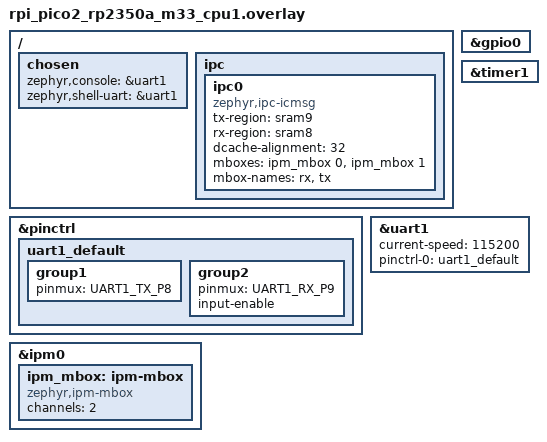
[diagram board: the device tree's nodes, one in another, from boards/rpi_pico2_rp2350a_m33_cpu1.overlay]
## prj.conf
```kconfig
CONFIG_PRINTK=y

CONFIG_IPC_SERVICE=y
CONFIG_IPC_SERVICE_BACKEND_ICMSG=y
CONFIG_MBOX=y

CONFIG_LOG=y
CONFIG_ASSERT=y

# CONFIG_ARCH_LOG_LEVEL_DBG=y
CONFIG_SOC_LOG_LEVEL_DBG=y
# CONFIG_KERNEL_LOG_LEVEL_DBG=y
CONFIG_MBOX_LOG_LEVEL_DBG=y
CONFIG_IPM_LOG_LEVEL_DBG=y
CONFIG_IPC_SERVICE_LOG_LEVEL_DBG=y
# CONFIG_LOG_DEFAULT_LEVEL=4
# CONFIG_LOG_OVERRIDE_LEVEL=4


CONFIG_LOG_MODE_DEFERRED=y
# CONFIG_LOG_MODE_MINIMAL=y
CONFIG_LOG_BUFFER_SIZE=16384
```

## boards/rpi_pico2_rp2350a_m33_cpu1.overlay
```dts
/*
 * Copyright (c) 2025 Dmitrii Sharshakov <d3dx12.xx@gmail.com>
 *
 * SPDX-License-Identifier: Apache-2.0
 */

gpio0_lo: &gpio0 {
	status = "okay";
};

&timer1 {
	status = "okay";
};

&pinctrl {
	uart1_default: uart1_default {
		group1 {
			pinmux = <UART1_TX_P8>;
		};

		group2 {
			pinmux = <UART1_RX_P9>;
			input-enable;
		};
	};
};

&uart1 {
	current-speed = <115200>;
	status = "okay";
	pinctrl-0 = <&uart1_default>;
	pinctrl-names = "default";
};

&ipm0 {
	ipm_mbox: ipm-mbox {
		compatible = "zephyr,ipm-mbox";
		#mbox-cells = <1>;
		channels = <2>;
		status = "okay";
	};
};

/ {
	chosen {
		zephyr,console = &uart1;
		zephyr,shell-uart = &uart1;
	};

	ipc {
		ipc0: ipc0 {
			compatible = "zephyr,ipc-icmsg";
			tx-region = <&sram9>;
			rx-region = <&sram8>;
			dcache-alignment = <32>;
			mboxes = <&ipm_mbox 0>, <&ipm_mbox 1>;
			mbox-names = "rx", "tx";
			status = "okay";
		};
	};
};
```

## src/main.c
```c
/*
 * Copyright (c) 2022 Nordic Semiconductor ASA
 *
 * SPDX-License-Identifier: Apache-2.0
 */

#include <zephyr/kernel.h>
#include <zephyr/device.h>

#include <zephyr/ipc/ipc_service.h>

#include "common.h"

#include <zephyr/logging/log.h>
LOG_MODULE_REGISTER(remote, LOG_LEVEL_INF);

#if defined(CONFIG_MULTITHREADING)
K_SEM_DEFINE(bound_sem, 0, 1);
#else
volatile uint32_t bound_sem = 1;
volatile uint32_t recv_sem = 1;
#endif

static unsigned char expected_message = 'a';
static size_t expected_len = PACKET_SIZE_START;
static size_t received;

static void ep_bound(void *priv)
{
	received = 0;
#if defined(CONFIG_MULTITHREADING)
	k_sem_give(&bound_sem);
#else
	bound_sem = 0;
#endif
	LOG_INF("Ep bounded");
}

static void ep_recv(const void *data, size_t len, void *priv)
{
#if defined(CONFIG_ASSERT)
	struct data_packet *packet = (struct data_packet *)data;

	__ASSERT(packet->data[0] == expected_message, "Unexpected message. Expected %c, got %c",
		expected_message, packet->data[0]);
	__ASSERT(len == expected_len, "Unexpected length. Expected %zu, got %zu",
		expected_len, len);
#endif

#ifndef CONFIG_MULTITHREADING
	recv_sem = 0;
#endif

	received += len;
	expected_message++;
	expected_len++;

	if (expected_message > 'z') {
		expected_message = 'a';
	}

	if (expected_len > sizeof(struct data_packet)) {
		expected_len = PACKET_SIZE_START;
	}
}

static int send_for_time(struct ipc_ept *ep, const int64_t sending_time_ms)
{
	struct data_packet msg = {.data[0] = 'A'};
	size_t mlen = PACKET_SIZE_START;
	size_t bytes_sent = 0;
	int ret = 0;

	LOG_INF("Perform sends for %lld [ms]", sending_time_ms);

	int64_t start = k_uptime_get();

	while ((k_uptime_get() - start) < sending_time_ms) {
		ret = ipc_service_send(ep, &msg, mlen);
		if (ret == -ENOMEM) {
			/* No space in the buffer. Retry. */
			ret = 0;
			continue;
		} else if (ret < 0) {
			LOG_ERR("Failed to send (%c) failed with ret %d", msg.data[0], ret);
			break;
		}
#if !defined(CONFIG_MULTITHREADING)
		else {
			recv_sem = 1;
		}
#endif

		msg.data[0]++;
		if (msg.data[0] > 'Z') {
			msg.data[0] = 'A';
		}

		bytes_sent += mlen;
		mlen++;

		if (mlen > sizeof(struct data_packet)) {
			mlen = PACKET_SIZE_START;
		}

#if defined(CONFIG_MULTITHREADING)
		k_usleep(1);
#else
		while ((recv_sem != 0) && ((k_uptime_get() - start) < sending_time_ms)) {
		};
#endif
	}

	LOG_INF("Sent %zu [Bytes] over %lld [ms]", bytes_sent, sending_time_ms);

	return ret;
}

static struct ipc_ept_cfg ep_cfg = {
	.cb = {
		.bound    = ep_bound,
		.received = ep_recv,
	},
};

int main(void)
{
	/*
	* Added delay here and say no logs after boot message. Implies deadlock is
	* not related to message passing, maybe driver/soc init?
	*/

	// k_msleep(1000);

	const struct device *ipc0_instance;
	struct ipc_ept ep;
	int ret;

	LOG_INF("IPC-service REMOTE demo started");

	ipc0_instance = DEVICE_DT_GET(DT_NODELABEL(ipc0));

	ret = ipc_service_open_instance(ipc0_instance);
	if ((ret < 0) && (ret != -EALREADY)) {
		LOG_ERR("ipc_service_open_instance() failure");
		return ret;
	}

	ret = ipc_service_register_endpoint(ipc0_instance, &ep, &ep_cfg);
	if (ret < 0) {
		LOG_ERR("ipc_service_register_endpoint() failure");
		return ret;
	}

#if defined(CONFIG_MULTITHREADING)
	k_sem_take(&bound_sem, K_FOREVER);
#else
	while (bound_sem != 0) {
	};
#endif

	ret = send_for_time(&ep, SENDING_TIME_MS);
	if (ret < 0) {
		LOG_ERR("send_for_time() failure");
		return ret;
	}

	LOG_INF("Received %zu [Bytes] in total", received);
	LOG_INF("IPC-service REMOTE demo ended");

	return 0;
}
```
